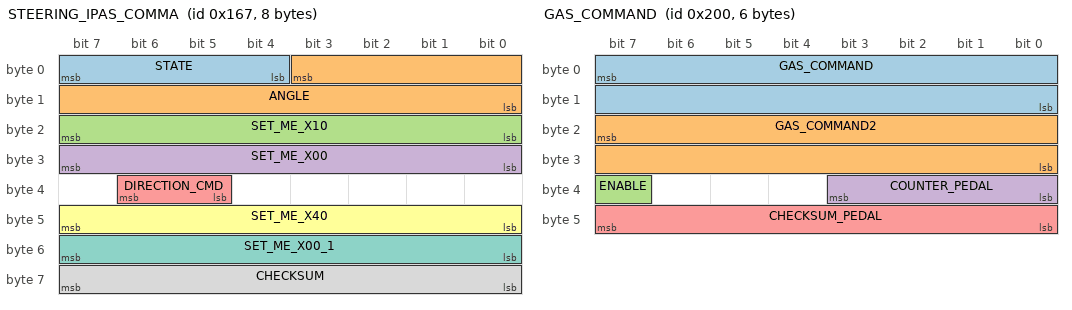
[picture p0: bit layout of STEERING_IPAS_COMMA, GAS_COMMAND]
BO_ 359 STEERING_IPAS_COMMA: 8 IPAS
 SG_ STATE : 7|4@0+ (1,0) [0|15] "" XXX
 SG_ ANGLE : 3|12@0- (1.5,0) [-510|510] "deg" XXX
 SG_ SET_ME_X10 : 23|8@0+ (1,0) [0|255] "" XXX
 SG_ SET_ME_X00 : 31|8@0+ (1,0) [0|255] "" XXX
 SG_ DIRECTION_CMD : 38|2@0+ (1,0) [0|3] "" XXX
 SG_ SET_ME_X40 : 47|8@0+ (1,0) [0|255] "" XXX
 SG_ SET_ME_X00_1 : 55|8@0+ (1,0) [0|255] "" XXX
 SG_ CHECKSUM : 63|8@0+ (1,0) [0|255] "" XXX

CM_ "BO_ STEERING_IPAS_COMMA: Copy of msg 614 so we can do angle control while the Park Assist ECU is connected (Panda spoofs 614 with 359 on connector J70). Note that addresses 0x266 and 0x167 are checksum-invariant";

BO_ 512 GAS_COMMAND: 6 EON
 SG_ GAS_COMMAND : 7|16@0+ (0.159375,-75.555) [0|1] "" INTERCEPTOR
 SG_ GAS_COMMAND2 : 23|16@0+ (0.159375,-151.111) [0|1] "" INTERCEPTOR
 SG_ ENABLE : 39|1@0+ (1,0) [0|1] "" INTERCEPTOR
 SG_ COUNTER_PEDAL : 35|4@0+ (1,0) [0|15] "" INTERCEPTOR
 SG_ CHECKSUM_PEDAL : 47|8@0+ (1,0) [0|255] "" INTERCEPTOR

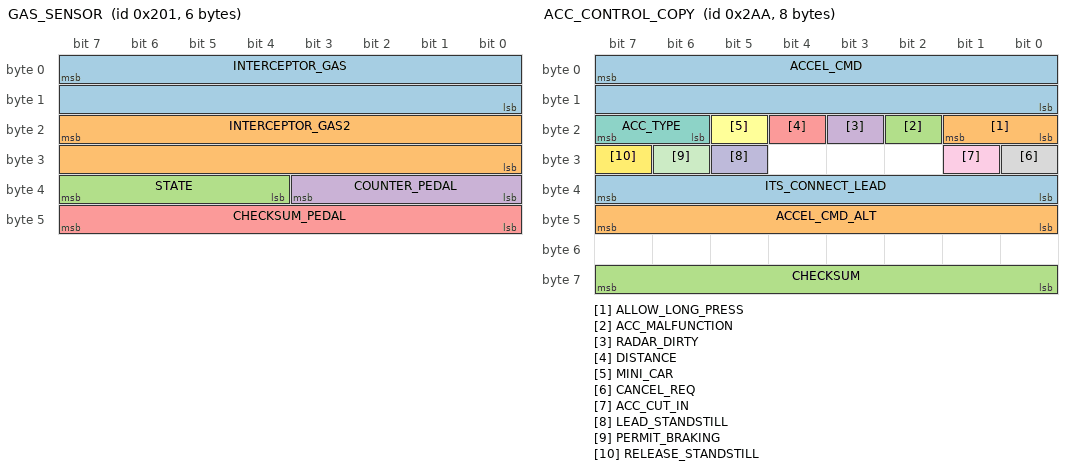
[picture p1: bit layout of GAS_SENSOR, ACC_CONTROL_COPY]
BO_ 513 GAS_SENSOR: 6 INTERCEPTOR
 SG_ INTERCEPTOR_GAS : 7|16@0+ (1,0) [0|1] "" EON
 SG_ INTERCEPTOR_GAS2 : 23|16@0+ (1,0) [0|1] "" EON
 SG_ STATE : 39|4@0+ (1,0) [0|15] "" EON
 SG_ COUNTER_PEDAL : 35|4@0+ (1,0) [0|15] "" EON
 SG_ CHECKSUM_PEDAL : 47|8@0+ (1,0) [0|255] "" EON

BO_ 682 ACC_CONTROL_COPY: 8 XXX
 SG_ ACCEL_CMD : 7|16@0- (0.001,0) [-20|20] "m/s^2" HCU
 SG_ ALLOW_LONG_PRESS : 17|2@0+ (1,0) [0|2] "" XXX
 SG_ ACC_MALFUNCTION : 18|1@0+ (1,0) [0|0] "" XXX
 SG_ RADAR_DIRTY : 19|1@0+ (1,0) [0|1] "" XXX
 SG_ DISTANCE : 20|1@0+ (1,0) [0|1] "" XXX
 SG_ MINI_CAR : 21|1@0+ (1,0) [0|1] "" XXX
 SG_ ACC_TYPE : 23|2@0+ (1,0) [0|3] "" HCU
 SG_ CANCEL_REQ : 24|1@0+ (1,0) [0|1] "" HCU
 SG_ ACC_CUT_IN : 25|1@0+ (1,0) [0|1] "" XXX
 SG_ LEAD_STANDSTILL : 29|1@0+ (1,0) [0|1] "" HCU
 SG_ PERMIT_BRAKING : 30|1@0+ (1,0) [0|1] "" HCU
 SG_ RELEASE_STANDSTILL : 31|1@0+ (1,0) [0|1] "" HCU
 SG_ ITS_CONNECT_LEAD : 39|8@0+ (1,0) [0|1] "" Vector__XXX
 SG_ ACCEL_CMD_ALT : 47|8@0- (0.05,0) [0|0] "m/s^2" XXX
 SG_ CHECKSUM : 63|8@0+ (1,0) [0|255] "" XXX

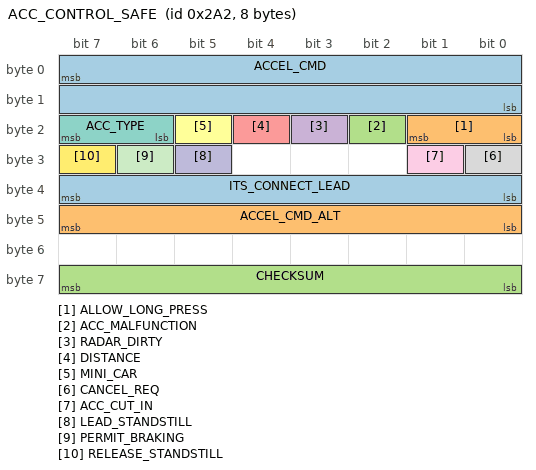
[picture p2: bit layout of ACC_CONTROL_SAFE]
BO_ 674 ACC_CONTROL_SAFE: 8 XXX
 SG_ ACCEL_CMD : 7|16@0- (0.001,0) [-20|20] "m/s^2" HCU
 SG_ ALLOW_LONG_PRESS : 17|2@0+ (1,0) [0|2] "" XXX
 SG_ ACC_MALFUNCTION : 18|1@0+ (1,0) [0|0] "" XXX
 SG_ RADAR_DIRTY : 19|1@0+ (1,0) [0|1] "" XXX
 SG_ DISTANCE : 20|1@0+ (1,0) [0|1] "" XXX
 SG_ MINI_CAR : 21|1@0+ (1,0) [0|1] "" XXX
 SG_ ACC_TYPE : 23|2@0+ (1,0) [0|3] "" HCU
 SG_ CANCEL_REQ : 24|1@0+ (1,0) [0|1] "" HCU
 SG_ ACC_CUT_IN : 25|1@0+ (1,0) [0|1] "" XXX
 SG_ LEAD_STANDSTILL : 29|1@0+ (1,0) [0|1] "" HCU
 SG_ PERMIT_BRAKING : 30|1@0+ (1,0) [0|1] "" HCU
 SG_ RELEASE_STANDSTILL : 31|1@0+ (1,0) [0|1] "" HCU
 SG_ ITS_CONNECT_LEAD : 39|8@0+ (1,0) [0|1] "" Vector__XXX
 SG_ ACCEL_CMD_ALT : 47|8@0- (0.05,0) [0|0] "m/s^2" XXX
 SG_ CHECKSUM : 63|8@0+ (1,0) [0|255] "" XXX

CM_ "BO_ ACC_CONTROL_COPY: CANFILTER is a CAN interceptor designed for NODSU CAMRY and CH-R: https://github.com/Smartype/canfilter, CANFILTER mirrors stock ACC_CONTROL with this msg id, this msg is used for canfiter detection, DISTANCE button event, and logging"
CM_ "BO_ ACC_CONTROL_SAFE: A ACC_CONTROL version which supports failsafe, when AEB is active, CANFILTER mutes ACC_CONTROL from OP and pass the stock msg instead"
CM_ "BO_ SECONDARY_STEER_ANGLE: ZSS is a high-precision steering angle sensor that can replace the lower resolution sensor in most TSS1 Toyotas. Learn more: https://github.com/commaai/openpilot/wiki/Toyota-Lexus#zorro-steering-sensor-zss";

VAL_ 513 STATE 5 "FAULT_TIMEOUT" 4 "FAULT_STARTUP" 3 "FAULT_SCE" 2 "FAULT_SEND" 1 "FAULT_BAD_CHECKSUM" 0 "NO_FAULT" ;

BO_ 35 SECONDARY_STEER_ANGLE: 8 XXX
 SG_ ZORRO_STEER : 7|24@0- (0.004901594652,0) [-500|500] "" XXX

BO_ 767 SDSU: 8 XXX
 SG_ FD_BUTTON : 7|1@0+ (1,0) [0|1] "" XXX

CM_ "BO_ SDSU: The sDSU is a modified DSU for use in TSS1 Toyotas. Learn more: https://github.com/wocsor/panda/tree/smart_dsu";
CM_ SG_ 767 FD_BUTTON "The follow distance button signal as forwarded by the sdsu";
